[part 4 of 4: packages /BMW/Boardnet/Clusters/CommunicationClusters to /Systems/ModeDeclarationGroups/FunctionalPartialNetworks]
AUTOSAR XML (schema 4-3-0)
package /BMW/Boardnet/Clusters/CommunicationClusters  (continued)
  flexray cluster A_FlexRay:  (continued)
    flexray physical channel A_FlexRay: comm-connectors=con_EPS_FibexID_0b7e5e09c061465d913e8968ece3cded, channel-name=CHANNEL-A  (continued)
      frame DT_DRDYSEN_EXT_VYAW_VEH: to EPS, category=APPLICATION, frame-length=14, flexray-absolutely-scheduled-timing{communication-cycle=cycle-repetition={base-cycle=0, cycle-repetition=CYCLE-REPETITION-2}, slot-id=56}, allow-dynamic-l-sdu-length=false, payload-preamble-indicator=false  # Daten Fahrdynamiksensor Erweitert / Giergeschwindigkeit Fahrzeug
        carries pdu PDUs/VYAW_VEH: packing-byte-order=little-endian, start-position=64
        pdu VYAW_VEH: length=6, transmission-mode-true-timing=cyclic-timing=time-period=0.01, unused-bit-pattern=255  # Giergeschwindigkeit Fahrzeug | Gemessene und plausibilisierte Giergeschwindigkeit des Fahrzeugs. Diese Nachricht wird nicht im EntryHU Gateway der PL7 geroutet.
          signal ALIV_VYAW_VEH: start 8, 4 bit, little-endian, base-type=uint8, invalid-value=value_15Dot0:15, compu-method=CompuMethodsForBoardnet/ALIV_COU_4, to EPS  # Alive_Giergeschwindigkeit_Fahrzeug / alive_yaw-velocity_vehicle | LogicalInterface:BMW.POWERTRAIN.SpeedAccelerationDistance[external]@Fahren;
          signal CRC_VYAW_VEH: start 0, 8 bit, little-endian, base-type=uint8, compu-method=CompuMethodsForBoardnet/CRC8, data-constr=DataConstraints/CRC8, to EPS  # CRC_Giergeschwindigkeit_Fahrzeug / CRC_yaw-velocity_vehicle | LogicalInterface:BMW.POWERTRAIN.SpeedAccelerationDistance[external]@Fahren; Standardabsicherung Applikations-CRC Dieses Signal verwendet die Applikations-CRC-ID = 14 (Dez)
          signal QU_VYAW_VEH: start 44, 4 bit, little-endian, base-type=uint8, invalid-value=value_15Dot0:15, compu {8=Initialisierung (QU_VYAW_VEH_Initialisierung) (Tritt während der Initialisierungsphase auf bis Ist-Wert verfügbar (Vorbefüllung). Nutzsignal wird permanent mit Nutzwert 0 befüllt.), 1=SignalwertIstGueltigUndAbgesichertUndPlausibilisiert (QU_VYAW_VEH_SignalwertIstGueltigUndAbgesichertUndPlausibilisiert) (Nutzsignal verfügbar, bereitgestellt aus zwei Sensoren (nur bei redundanter Sensorik) elektrische und Modellüberwachung i.O. / BNE original name: Signalwert ist gültig und abgesichert und plausibilisiert), 9=SignalwertIstGueltigUndAbgesichertZustandSlashStatusTemporaer (QU_VYAW_VEH_SignalwertIstGueltigUndAbgesichertZustandSlashStatusTemporaer) (Nutzsignal verfügbar, bereitgestellt aus zwei Sensoren (nur bei redundanter Sensorik) elektrische und Modellüberwachung i.O. Es liegt eine Signaltoleranz aufgrund nicht abgeschlossenen Offsetabgleichs an. FuSi : Bei sicherheitsrelevanten Funktionen ist die Fehleramplitude auszuwerten / BNE original name: Signalwert ist gültig und abgesichert, Zustand/Status temporär), 2=SignalwertIstGueltig (QU_VYAW_VEH_SignalwertIstGueltig) (Nutzsignal verfügbar, bereitgestellt aus einem Sensor elektrische und Modellüberwachung i.O. / BNE original name: Signalwert ist gültig), 10=SignalwertIstGueltigZustandSlashStatusTemporaer (QU_VYAW_VEH_SignalwertIstGueltigZustandSlashStatusTemporaer) (Nutzsignal verfügbar, bereitgestellt aus einem Sensor elektrische und Modellüberwachung i.O. Es liegt eine Signaltoleranz aufgrund nicht abgeschlossenen Offsetabgleichs an. FuSi : Bei sicherheitsrelevanten Funktionen ist die Fehleramplitude auszuwerten. / BNE original name: Signalwert ist gültig, Zustand/Status temporär), 3=SignalqualitaetBzwDotUeberwachungEingeschraenkt (QU_VYAW_VEH_SignalqualitaetBzwDotUeberwachungEingeschraenkt) (keine Modellüberwachung, da Eingangsgrößen für Überwachung fehlen (zum Bsp. Querbeschleunigung, Lenkwinkel, ...), elektrische Überwachung i.O Nutzsignal wird aus Sensorwert gebildet. FuSi: keine Verwendung für sicherheitsrelevante Funktionen / BNE original name: Signalqualität bzw. Überwachung eingeschränkt), 11=SignalqualitaetBzwDotUeberwachungEingeschraenktZustandSlashStatusTemporaer (QU_VYAW_VEH_SignalqualitaetBzwDotUeberwachungEingeschraenktZustandSlashStatusTemporaer) (keine Modellüberwachung, da Eingangsgrößen für Überwachung fehlen (zum Bsp. Querbeschleunigung, Lenkwinkel, ...), elektrische Überwachung i.O Es liegt eine Signaltoleranz aufgrund nicht abgeschlossenen Offsetabgleichs an. Nutzsignal wird aus Sensorwert gebildet. FuSi : Bei sicherheitsrelevanten Funktionen ist die Fehleramplitude auszuwerten / BNE original name: Signalqualität bzw. Überwachung eingeschränkt, Zustand/Status temporär), 4=Reserved (QU_VYAW_VEH_Reserved), 12=ErsatzwertColonAbgleichwertIstImNutzsignalGesetztZustandSlashStatusTemporaer (QU_VYAW_VEH_ErsatzwertColonAbgleichwertIstImNutzsignalGesetztZustandSlashStatusTemporaer) (elektrische Überwachung oder Modellüberwachung zeigt Fehler an, deshalb wird Ersatzwert aus Modell (Lenkwinkel) versendet FuSi: keine Verwendung für sicherheitsrelevante Funktionen / BNE original name: Ersatzwert: Abgleichwert ist im Nutzsignal gesetzt, Zustand/Status temporär), 6=SignalwertIstUngueltig (QU_VYAW_VEH_SignalwertIstUngueltig) (elektrische Überwachung oder Modellüberwachung zeigt Fehler an, kein Ersatzwert verfügbar (Steuergerät interner Fehler). Das zugehörige Nutzsignal wird permanent mit der Ungültigkeitskennung befüllt. Diese Codierung wird ab SP2015 nicht mehr bedient. / BNE original name: Signalwert ist ungültig), 14=SignalwertIstUngueltigZustandSlashStatusTemporaer (QU_VYAW_VEH_SignalwertIstUngueltigZustandSlashStatusTemporaer) (elektrische Überwachung oder Modellüberwachung zeigt Fehler an, kein Ersatzwert verfügbar (Eingangssignale Fehler). Das zugehörige Nutzsignal wird permanent mit der Ungültigkeitskennung befüllt. / BNE original name: Signalwert ist ungültig, Zustand/Status temporär), 7=Reserved_bne_7C322122A3AD4C1BBA9012320D4729F1_7 (QU_VYAW_VEH_Reserved_bne_7C322122A3AD4C1BBA9012320D4729F1_7) (BNE original name: Reserved), 15=SignalUngueltig (QU_VYAW_VEH_SignalUngueltig) (Kann nur vom Gateway gesetzt werden / BNE original name: Signal ungültig)} "Qualifier_Giergeschwindigkeit_Fahrzeug / Qualifier_yaw-velocity_vehicle", to EPS  # Qualifier_Giergeschwindigkeit_Fahrzeug / Qualifier_yaw-velocity_vehicle | LogicalInterface:BMW.POWERTRAIN.SpeedAccelerationDistance[external]@Fahren; Erweiterter Status Qualifier zum Signal Giergeschwindigkeit_Fahrzeug. Mindestanforderungen um einen gültigen Signalwert senden zu können (Stand 10.06.08 gilt für L6/L7/F25): - Klemme 30B + Geschwindigkeit_Fahrzeug_Schwerpunkt gültig + Lenkwinkel_Vorderachse_effektiv gültig alternative Aufstartbedingung: - Bei Erkennung eines Modellfehlers wird bei Kl.15 Änderung ein Reset durchgeführt. Frühestens 50ms später kann ein gültiger Wert kommen. In dieser Zeit wird der Qualifier auf Initialisierung gesetzt. Ab der F010-10-01-350 gibt es baureihenübergreifend folgende Spezifikationsänderung: Wenn der Gierratensensor im Anschlag ist (z. Bsp. bei der Rückwärtsschleuderwende), wird nicht wie bisher auf VYAW_VEH ein Ersatzwert und im Qualifier die Codierung 12 (dec) gesendet, sondern es wird der begrenzte Wert ausgegeben und der Qualifier bleibt auf gültig.
          signal VYAW_VEH: start 16, 16 bit, little-endian, base-type=uint16, invalid-value=value_65535Dot0:65535, compu {phys=raw*0.005-163.84 for raw 32768..13139567.999999998; unit °/s} "Transp.MOST-GW-Migration, 01.09.2006: Zusammenführung der Signalklasse Giergeschwindigkeit_Fahrzeug [1] mit den Parametern YawVelocityVehicle [1].", range phys 0..65534 °/s "Transp.MOST-GW-Migration, 01.09.2006: Zusammenführung der Signalklasse Giergeschwindigkeit_Fahrzeug [1] mit den Parametern YawVelocityVehicle [1].", to EPS  # Giergeschwindigkeit_Fahrzeug / yaw-velocity_vehicle | LogicalInterface:BMW.POWERTRAIN.SpeedAccelerationDistance[external]@Fahren; Giergeschwindigkeit des Fahrzeugs. Richtung nach ISO 8855 (positiver Winkel entspricht Drehung gegen den Uhrzeigersinn). Die Giergeschwindigkeit des Fahrzeuges wird je nach Fahrzeugkonfiguration von einem oder zwei Gierratensensoren gemessen. Es erfolgt eine Plausibilisierung (durch Modellüberwachung, Gradientenüberwachung und Redundanzüberwachung bei zwei Sensoren) und ein Langzeitabgleich der Offset-Drifts. Sind zwei Gierratensensoren verbaut, so wird der Mittelwert der abgeglichenen Signale als Gierratennutzsignal ausgegeben. Ist einer von zwei Gierratensensoren als fehlerhaft erkannt, so wird der Wert des verbleibenden Sensors als Nutzsignal ausgegeben. Im Qualifier erfolgt die Rückstufung des Signals von "gültig + abgesichert" auf "gültig". Die Einstufung "gültig" gilt entsprechend auch dann, wenn nur ein Gierratensensor verbaut und fehlerfrei ist. Sind alle im Fzg. verbauten Gierratensensoren als fehlerhaft erkannt, so wird ein Ersatzwert aus den verbleibenden Sensoren im Fzg. (Raddrehzahlen, Lenkwinkel, Querbeschleunigung) berechnet und ausgegeben. Entsprechend erfolgt die Kennzeichnung "Ersatzwert" durch den Qualifier. Transp.MOST-GW-Migration, 01.09.2006: Zusammenführung des Parameters YawVelocityVehicle [1] mit dem Signal Giergeschwindigkeit_Fahrzeug [3].
          signal VYAW_VEH_ERR_AMP: start 32, 12 bit, little-endian, base-type=uint16, invalid-value=value_4095Dot0:4095, compu {phys=raw*0.0125 for raw 0..320000; unit °/s} "Quantisierung ist temporär", range phys 0..4000 °/s "Quantisierung ist temporär", to EPS  # Giergeschwindigkeit_Fahrzeug_Fehler_Amplitude / yaw-velocity_vehicle_error_amplitude | LogicalInterface:BMW.POWERTRAIN.SpeedAccelerationDistance[external]@Fahren; Für den Fall, dass ein Sensorfehler nicht oder noch nicht erkannt wurde, interne Überwachungsmaßnahmen jedoch anzeigen, dass eine Abweichung des Sensorsignals vom tatsächlichen Wert vorliegen könnte, gibt dieser Wert an, wie groß diese Abweichung maximal sein kann. Es wird der Betrag der Fehleramplitude ausgegeben, die Abweichung des tatsächlichen Signals vom ausgegebenen Signal liegt in einem Band mit der doppelten Breite der Fehleramplitude (Signal plus oder minus Fehleramplitude). Der Qualifier des Nutzsignals behält in diesem Fall seinen bisherigen Wert. Beispiel: zwei nicht als fehlerhaft erkannte Gierratensensoren liefern die Werte 10°/s und 20°/s. Das ausgegebene Nutzsignal hat in diesem Fall einen Wert von 15°/s, die Fehleramplitude einen Wert von 5°/s.
          signal VYAW_VEH_dummy_12_15: start 12, 4 bit, little-endian, base-type=uint8, compu {identical}, range phys 0..15, to EPS
          mapping sigGroup_VYAW_VEH: i-signal-group=sigGroup_VYAW_VEH
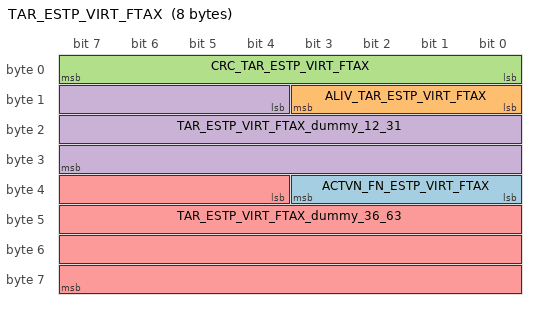
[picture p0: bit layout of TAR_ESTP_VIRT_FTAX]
      frame TAR_ESTP_VIRT_FTAX: to EPS, category=APPLICATION, frame-length=8, flexray-absolutely-scheduled-timing{communication-cycle=cycle-repetition={base-cycle=1, cycle-repetition=CYCLE-REPETITION-2}, slot-id=65}, allow-dynamic-l-sdu-length=false, payload-preamble-indicator=false  # Soll Endanschlag Virtuell Vorderachse
        pdu TAR_ESTP_VIRT_FTAX: length=8, transmission-mode-true-timing=cyclic-timing=time-period=0.01, unused-bit-pattern=255  # Soll Endanschlag Virtuell Vorderachse
          signal ACTVN_FN_ESTP_VIRT_FTAX: start 32, 4 bit, little-endian, base-type=uint8, invalid-value=value_15Dot0:15, compu {0=FunktionVirtuellerEndanschlagDeaktivieren (ACTVN_FN_ESTP_VIRT_FTAX_FunktionVirtuellerEndanschlagDeaktivieren) (Funktion virtueller Endanschlag deaktivieren durch Fahrzeugführung / BNE original name: Funktion virtueller Endanschlag deaktivieren), 1=FunktionVirtuellerEndanschlagAktivieren (ACTVN_FN_ESTP_VIRT_FTAX_FunktionVirtuellerEndanschlagAktivieren) (Funktion virtueller Endanschlag aktivieren durch Fahrzeugführung / BNE original name: Funktion virtueller Endanschlag aktivieren), 13=Funktionsschnittstelle_ist_nicht_verfuegbar (ACTVN_FN_ESTP_VIRT_FTAX_Funktionsschnittstelle_ist_nicht_verfuegbar) (Sendefunktion in Betrieb, Werte nicht verfügbar), 14=Funktion_meldet_Fehler (ACTVN_FN_ESTP_VIRT_FTAX_Funktion_meldet_Fehler) (Sendefunktion in Betrieb, meldet Fehler), 15=Signal_unbefuellt (ACTVN_FN_ESTP_VIRT_FTAX_Signal_unbefuellt) (Sendefunktion nicht in Betrieb)} "Aktivierung_Funktion_Endanschlag_Virtuell_Vorderachse / activation_function_end-stop_virtual_front-axle", to EPS  # Aktivierung_Funktion_Endanschlag_Virtuell_Vorderachse / activation_function_end-stop_virtual_front-axle | LogicalInterface:BMW.CHASSIS.STEERING.SteeringAngle[internal]@Fahren; Dieses Signal gibt an, ob der virtuelle Endanschlag der EPS aktiviert bzw. deaktiviert werden soll.
          signal ALIV_TAR_ESTP_VIRT_FTAX: start 8, 4 bit, little-endian, base-type=uint8, invalid-value=value_15Dot0:15, compu {identical}, range phys 0..14, to EPS  # Alive_Soll_Endanschlag_Virtuell_Vorderachse / alive_target_end-stop_virtual_front-axle | LogicalInterface:BMW.CHASSIS.STEERING.SteeringAngle[internal]@Fahren; Standardabsicherung Alivezähler laut Definition per Lastenheft Allgemeine Bordnetzkommunikation Dieses Signal soll nur überwacht werden, wenn Aktivlenkung und ein Lenksäulensteller verbaut sind.
          signal CRC_TAR_ESTP_VIRT_FTAX: start 0, 8 bit, little-endian, base-type=uint8, compu-method=CompuMethodsForBoardnet/CRC8, data-constr=DataConstraints/CRC8, to EPS  # CRC_Soll_Endanschlag_Virtuell_Vorderachse / CRC_target_end-stop_virtual_front-axle | LogicalInterface:BMW.CHASSIS.STEERING.SteeringAngle[internal]@Fahren; Dieses Signal verwendet die Applikations-CRC-ID = 52 (Dez) Dieses Signal soll nur überwacht werden, wenn Aktivlenkung und ein Lenksäulensteller verbaut sind.
          signal TAR_ESTP_VIRT_FTAX_dummy_12_31: start 12, 20 bit, little-endian, base-type=uint32, compu {identical}, range phys 0..1048575, to EPS
          signal TAR_ESTP_VIRT_FTAX_dummy_36_63: start 36, 28 bit, little-endian, base-type=uint32, compu {identical}, range phys 0..268435455, to EPS
          mapping sigGroup_TAR_ESTP_VIRT_FTAX: i-signal-group=sigGroup_TAR_ESTP_VIRT_FTAX
      frame TAR_QTA_STRMOM_DV_TAR_STMOM_DV_ACT: to EPS, category=APPLICATION, frame-length=16, flexray-absolutely-scheduled-timing{communication-cycle=cycle-repetition={base-cycle=0, cycle-repetition=CYCLE-REPETITION-2}, slot-id=68}, allow-dynamic-l-sdu-length=false, payload-preamble-indicator=false  # Soll Anteil Lenkmoment Fahrer / Soll Lenkmoment Fahrer Stellglied / target quota steering-moment driver / Soll Lenkmoment Fahrer Stellglied | Soll-Offset-Handmoment.
        pdu TAR_QTA_STRMOM_DV: length=8, transmission-mode-true-timing=cyclic-timing=time-period=0.01, unused-bit-pattern=255  # Soll Anteil Lenkmoment Fahrer / target quota steering-moment Fahrer | Diese Nachricht wird nur bei Fahrzeugen mit elektrischer Lenkung unterstützt. Soll-Offset-Handmoment
          signal ALIV_TAR_QTA_STMOM_DV: start 8, 4 bit, little-endian, base-type=uint8, invalid-value=value_15Dot0:15, compu-method=CompuMethodsForBoardnet/ALIV_COU_4, to EPS  # Alive_Soll_Anteil_Lenkmoment_Fahrer / alive_target_quota_steering-moment_driver | LogicalInterface:BMW.CHASSIS.STEERING.SteeringAngle[internal]@Fahren; Standardabsicherung Alivezähler laut Definition per Lastenheft Allgemeine Bordnetzkommunikation.
          signal CRC_TAR_QTA_STMOM_DV: start 0, 8 bit, little-endian, base-type=uint8, compu-method=CompuMethodsForBoardnet/CRC8, data-constr=DataConstraints/CRC8, to EPS  # CRC_Soll_Anteil_Lenkmoment_Fahrer / CRC_target_quota_steering-moment_driver | LogicalInterface:BMW.CHASSIS.STEERING.SteeringAngle[internal]@Fahren; Standardabsicherung Applikations-CRC laut Definition per Lastenheft Allgemeine Bordnetzkommunikation. Dieses Signal verwendet die Applikations-CRC-ID = 109 (Dez)
          signal CTR_DEAC_EPS_FNS: start 60, 4 bit, little-endian, base-type=uint8, invalid-value=value_15Dot0:15, compu {mask 15: 0=Keine_Deaktivierung_EPS_Funktionen (CTR_DEAC_EPS_FNS_Keine_Deaktivierung_EPS_Funktionen) (Es besteht keine Anforderung zur Deaktivierung von Funktionen auf der EPS.), mask 15: 13=Funktionsschnittstelle_ist_nicht_verfuegbar (CTR_DEAC_EPS_FNS_Funktionsschnittstelle_ist_nicht_verfuegbar) (Sendefunktion in Betrieb, Werte nicht verfügbar), mask 15: 14=Funktion_meldet_Fehler (CTR_DEAC_EPS_FNS_Funktion_meldet_Fehler) (Sendefunktion in Betrieb, meldet Fehler), mask 15: 15=Signal_unbefuellt (CTR_DEAC_EPS_FNS_Signal_unbefuellt) (Wird nicht aktiv gesetzt), mask 9: 1=Deaktivierung_EPS_Funktionen_Funktionsgruppe_1 (CTR_DEAC_EPS_FNS_Deaktivierung_EPS_Funktionen_Funktionsgruppe_1) (Anforderung zur Deaktivierung einer spezifizierten Funktionsgruppe 1 auf der EPS. Die detaillierte Spezifikation der Funktionsgruppe 1 erfolgt im Entwicklungsprozess mit den Lieferanten. / BNE original name: Deaktivierung_EPS_Funktionen_ Funktionsgruppe_1), mask 10: 2=Deaktivierung_EPS_Funktionen_Funktionsgruppe_2 (CTR_DEAC_EPS_FNS_Deaktivierung_EPS_Funktionen_Funktionsgruppe_2) (Anforderung zur Deaktivierung einer spezifizierten Funktionsgruppe 2 auf der EPS. Die detaillierte Spezifikation der Funktionsgruppe 2 erfolgt im Entwicklungsprozess mit den Lieferanten. / BNE original name: Deaktivierung_EPS_Funktionen_ Funktionsgruppe_2)} "Steuerung_Deaktivierung_EPS_Funktionen / control_deactivation_EPS_functions", to EPS  # Steuerung_Deaktivierung_EPS_Funktionen / control_deactivation_EPS_functions | LogicalInterface:BMW.CHASSIS.STEERING.SteeringAngle[internal]@Fahren; Dieses Signal beinhaltet die Information zur Deaktivierung einzelner Funktionen auf der EPS.
          signal FACT_ASS_STMOM_FTAX: start 48, 8 bit, little-endian, base-type=uint8, invalid-value=value_255Dot0:255, compu {phys=raw/256+1 for raw -256..64768}, range phys 0..254, to EPS  # Faktor_Unterstützung_Lenkmoment_Vorderachse / factor_assistance_steering-moment_front-axle | LogicalInterface:BMW.CHASSIS.STEERING.SteeringAngle[internal]@Fahren; Dieser Faktor wird als Multiplikator für den Steuerung der Lenkunterstützungsberechnung benötigt. Vollständige Quantisierung/Offsetsangabe: (PH) = 0.00390625 * (HEX) + 1
          signal FACT_CTRR_STMOM_FTAX: start 32, 8 bit, little-endian, base-type=uint8, invalid-value=value_255Dot0:255, compu {phys=raw/256+0.0078125 for raw -2..65022}, range phys 0..254, to EPS  # Faktor_Zentrierung_Lenkmoment_Vorderachse / factor_centering_steering-moment_front-axle | LogicalInterface:BMW.CHASSIS.STEERING.SteeringAngle[internal]@Fahren; Dieser Faktor wird als Multiplikator für den Steuerung des Aktiven Rücklaufs benötigt. Vollständige Quantisierung/Offsetsangabe: (PH) = 0.00390625 * (HEX) + 0,0078125
          signal FACT_DMPNG_STMOM_FTAX: start 40, 8 bit, little-endian, base-type=uint8, invalid-value=value_255Dot0:255, compu {phys=raw/256+0.0078125 for raw -2..65022}, range phys 0..254, to EPS  # Faktor_Dämpfung_Lenkmoment_Vorderachse / factor_damping_steering-moment_front-axle | LogicalInterface:BMW.CHASSIS.STEERING.SteeringAngle[internal]@Fahren; Dieser Faktor wird als Multiplikator für den Steuerung des Aktiven Rücklaufs benötigt. Vollständige Quantisierung/Offsetsangabe: (PH) = 0.00390625 * (HEX) + 0.0078125
          signal QU_TAR_FACT_STMOM_FTAX: start 56, 4 bit, little-endian, base-type=uint8, invalid-value=value_15Dot0:15, compu {2=SollwerteUmsetzen (QU_TAR_FACT_STMOM_FTAX_SollwerteUmsetzen) (Es wird ein Lenkmoment angefordert. / BNE original name: Sollwerte umsetzen), 7=SollwerteNichtVorhanden (QU_TAR_FACT_STMOM_FTAX_SollwerteNichtVorhanden) (Wird immer gesetzt wenn keine EPS verbaut ist. / BNE original name: Sollwerte nicht vorhanden), 14=StandbyColonSollwerteNichtUmsetzen (QU_TAR_FACT_STMOM_FTAX_StandbyColonSollwerteNichtUmsetzen) (Es wird kein Moment angefordert. Wird auch im Fehlerfall gesetzt. / BNE original name: Standby: Sollwerte nicht umsetzen), 15=SignalUngueltig (QU_TAR_FACT_STMOM_FTAX_SignalUngueltig) (Wird nicht aktiv gesetzt / BNE original name: Signal ungültig)} "Qualifier_Soll_Faktor_Lenkmoment_Vorderachse / Qualifier_target_factor_steering-moment_front-axle", to EPS  # Qualifier_Soll_Faktor_Lenkmoment_Vorderachse / Qualifier_target_factor_steering-moment_front-axle | LogicalInterface:BMW.CHASSIS.STEERING.SteeringAngle[internal]@Fahren; Sollwertqualifier zu den Signalen Faktor_Unterstützung_Lenkmoment_Vorderachse, Faktor_Dämpfung_Lenkmoment_Vorderachse, Faktor_Zentrierung_Lenkmoment_Vorderachse
          signal QU_TAR_QTA_STMOM_DV: start 28, 4 bit, little-endian, base-type=uint8, invalid-value=value_15Dot0:15, compu {2=SollwerteUmsetzen (QU_TAR_QTA_STMOM_DV_SollwerteUmsetzen) (Es wird ein Lenkmoment angefordert. / BNE original name: Sollwerte umsetzen), 7=SollwerteNichtVorhanden (QU_TAR_QTA_STMOM_DV_SollwerteNichtVorhanden) (Wird gesendet, wenn die Funktion auscodiert ist. Wird immer gesetzt wenn keine EPS verbaut ist. / BNE original name: Sollwerte nicht vorhanden), 14=SollwerteNichtUmsetzen_Standby (QU_TAR_QTA_STMOM_DV_SollwerteNichtUmsetzen_Standby) (Es wird kein Moment angefordert. / BNE original name: Sollwerte nicht umsetzen - Standby), 15=SignalUngueltig (QU_TAR_QTA_STMOM_DV_SignalUngueltig) (Wird nicht aktiv gesetzt / BNE original name: Signal ungültig)} "Qualifier_Soll_Anteil_Lenkmoment_Fahrer / Qualifier_target_quota_steering-moment_driver", to EPS  # Qualifier_Soll_Anteil_Lenkmoment_Fahrer / Qualifier_target_quota_steering-moment_driver | LogicalInterface:BMW.CHASSIS.STEERING.SteeringAngle[internal]@Fahren; Sollwert-Qualifier zum Signal Soll_Anteil_Lenkmoment_Fahrer
          signal TAR_QTA_STMOM_DV: start 16, 12 bit, little-endian, base-type=uint16, invalid-value=value_4095Dot0:4095, compu {phys=raw*0.005-10 for raw 2000..802000; unit NwtMtr}, range phys 0..4000 NwtMtr, to EPS  # Soll_Anteil_Lenkmoment_Fahrer / target_quota_steering-moment_driver | LogicalInterface:BMW.CHASSIS.STABILIZATION.VehicleDynamicParameters[internal]@Fahren; Es handelt sich um das Offset-Handmoment des Lenkrades, das im Gegenuhrzeigersinn positiv gezählt wird.
          signal TAR_QTA_STRMOM_DV_dummy_12_15: start 12, 4 bit, little-endian, base-type=uint8, compu {identical}, range phys 0..15, to EPS
          mapping sigGroup_TAR_QTA_STRMOM_DV: i-signal-group=sigGroup_TAR_QTA_STRMOM_DV
        carries pdu PDUs/TAR_STMOM_DV_ACT: packing-byte-order=little-endian, start-position=64
        pdu TAR_STMOM_DV_ACT: length=8, transmission-mode-true-timing=cyclic-timing=time-period=0.01, unused-bit-pattern=255  # Soll Lenkmoment Fahrer Stellglied | Diese Nachricht wird nur bei Fahrzeugen mit elektrischer Lenkung unterstützt. Das angegebene Offsetmoment wird vom ICM_QL Momentkoordinator gesendet und hinter der Reglerschleife aufaddiert, um eine direkte Korrekturmöglichkeit der Stellwerte zu haben.
          signal ALIV_TAR_STMOM_DV_ACT: start 8, 4 bit, little-endian, base-type=uint8, invalid-value=value_15Dot0:15, compu-method=CompuMethodsForBoardnet/ALIV_COU_4, to EPS  # Alive_Soll_Lenkmoment_Fahrer_Stellglied / alive_target_steering-moment_driver_actuator | LogicalInterface:BMW.CHASSIS.STABILIZATION.VehicleDynamicParameters[internal]@Fahren; Standardabsicherung Alivezähler laut Definition per Lastenheft Allgemeine Bordnetzkommunikation.
          signal CRC_TAR_STMOM_DV_ACT: start 0, 8 bit, little-endian, base-type=uint8, compu-method=CompuMethodsForBoardnet/CRC8, data-constr=DataConstraints/CRC8, to EPS  # CRC_Soll_Lenkmoment_Fahrer_Stellglied / CRC_target_steering-moment_driver_actuator | LogicalInterface:BMW.CHASSIS.STABILIZATION.VehicleDynamicParameters[internal]@Fahren; Standardabsicherung Applikations-CRC laut Definition per Lastenheft Allgemeine Bordnetzkommunikation. Dieses Signal verwendet die Applikations-CRC-ID = 179 (Dez)
          signal FACT_DMPNG_ADDON_STMOM_FTAX: start 56, 8 bit, little-endian, base-type=uint8, invalid-value=value_255Dot0:255, compu {phys=raw/64 for raw 0..8192, 253=Reserviert (FACT_DMPNG_ADDON_STMOM_FTAX_Reserviert) (Hinweis: Reserviert für funktionale Kennung Signal-Tag.), 254=Reserviert_bne_5B8A124DE2884D68A663388C50F241EF_254 (FACT_DMPNG_ADDON_STMOM_FTAX_Reserviert_bne_5B8A124DE2884D68A663388C50F241EF_254) (Hinweis: Reserviert für funktionale Kennung Signal-Tag. / BNE original name: Reserviert), 255=Signal_unbefuellt (FACT_DMPNG_ADDON_STMOM_FTAX_Signal_unbefuellt) (Sendefunktion nicht in Betrieb)} "Faktor_Dämpfung_Zusatz_Lenkmoment_Vorderachse / factor_damping_add-on_steering-moment_front-axle", range phys 0..128 "Faktor_Dämpfung_Zusatz_Lenkmoment_Vorderachse / factor_damping_add-on_steering-moment_front-axle", to EPS  # Faktor_Dämpfung_Zusatz_Lenkmoment_Vorderachse / factor_damping_add-on_steering-moment_front-axle | LogicalInterface:BMW.CHASSIS.STABILIZATION.VehicleDynamicParameters[internal]@Fahren; Skalierung der Zusatzdämpfung in der EPS für steife Lenkwinkelregelung in der SWC QdmZff.
          signal QU_TAR_DMPNG_ADDON_STMOM_FTAX: start 52, 4 bit, little-endian, base-type=uint8, invalid-value=value_15Dot0:15, compu {1=SollwertZusatzdaempfungNichtUmsetzen (QU_TAR_DMPNG_ADDON_STMOM_FTAX_SollwertZusatzdaempfungNichtUmsetzen) (BNE original name: Sollwert Zusatzdämpfung nicht umsetzen), 2=SollwertZusatzdaempfungUmsetzen (QU_TAR_DMPNG_ADDON_STMOM_FTAX_SollwertZusatzdaempfungUmsetzen) (BNE original name: Sollwert Zusatzdämpfung umsetzen), 15=SignalUnbefuellt (QU_TAR_DMPNG_ADDON_STMOM_FTAX_SignalUnbefuellt) (Wird nicht aktiv gesetzt / BNE original name: Signal unbefüllt)} "Qualifier_Soll_Dämpfung_Zusatz_Lenkmoment_Vorderachse / Qualifier_target_damping_add-on_steering-moment_front-axle", to EPS  # Qualifier_Soll_Dämpfung_Zusatz_Lenkmoment_Vorderachse / Qualifier_target_damping_add-on_steering-moment_front-axle | LogicalInterface:BMW.CHASSIS.STABILIZATION.VehicleDynamicParameters[internal]@Fahren; Sollwertqualifier zum Signal Faktor_Dämpfung_Zusatz_Lenkmoment_Vorderachse
          signal QU_TAR_STMOM_DV_ACT: start 28, 4 bit, little-endian, base-type=uint8, invalid-value=value_15Dot0:15, compu {2=SollwerteUmsetzen (QU_TAR_STMOM_DV_ACT_SollwerteUmsetzen) (Es wird ein Lenkmoment angefordert. / BNE original name: Sollwerte umsetzen), 7=SollwerteNichtVorhanden (QU_TAR_STMOM_DV_ACT_SollwerteNichtVorhanden) (Wird immer gesetzt wenn keine EPS verbaut ist / BNE original name: Sollwerte nicht vorhanden), 14=StandbyColonSollwerteNichtUmsetzen (QU_TAR_STMOM_DV_ACT_StandbyColonSollwerteNichtUmsetzen) (Es wird kein Moment angefordert. Wird auch im Fehlerfall gesetzt. / BNE original name: Standby: Sollwerte nicht umsetzen), 15=SignalUngueltig (QU_TAR_STMOM_DV_ACT_SignalUngueltig) (Wird nicht aktiv gesetzt / BNE original name: Signal ungültig)} "Qualifier_Soll_Lenkmoment_Fahrer_Stellglied / Qualifier_target_steering-moment_driver_actuator", to EPS  # Qualifier_Soll_Lenkmoment_Fahrer_Stellglied / Qualifier_target_steering-moment_driver_actuator | LogicalInterface:BMW.CHASSIS.STABILIZATION.VehicleDynamicParameters[internal]@Fahren; Sollwertqualifier zum Signal Soll_Lenkmoment_Fahrer_Stellglied
          signal TAR_STMOM_DV_ACT: start 16, 12 bit, little-endian, base-type=uint16, invalid-value=value_4095Dot0:4095, compu {phys=raw*0.006-12 for raw 2000..668666.6666666666; unit NwtMtr}, range phys 0..4000 NwtMtr, to EPS  # Soll_Lenkmoment_Fahrer_Stellglied / target_steering-moment_driver_actuator | LogicalInterface:BMW.CHASSIS.STABILIZATION.VehicleDynamicParameters[internal]@Fahren; Gestelltes Motormoment für den EPS Aktuator. Offsetmoment (+/-1Nm).
          signal TAR_STMOM_DV_ACT_dummy_12_15: start 12, 4 bit, little-endian, base-type=uint8, compu {identical}, range phys 0..15, to EPS
          signal TAR_STMOM_DV_ACT_dummy_32_51: start 32, 20 bit, little-endian, base-type=uint32, compu {identical}, range phys 0..1048575, to EPS
          mapping sigGroup_TAR_STMOM_DV_ACT: i-signal-group=sigGroup_TAR_STMOM_DV_ACT
      frame ENERG_DGR_DRDY: to EPS, category=APPLICATION, frame-length=8, flexray-absolutely-scheduled-timing{communication-cycle=cycle-repetition={base-cycle=1, cycle-repetition=CYCLE-REPETITION-2}, slot-id=68}, allow-dynamic-l-sdu-length=false, payload-preamble-indicator=false  # Energie Degradation Fahrdynamik
        pdu ENERG_DGR_DRDY: length=8, transmission-mode-true-timing=cyclic-timing=time-period={tolerance=absolute-tolerance=0.002, value=0.01}, unused-bit-pattern=255  # Energie Degradation Fahrdynamik | Energie Degradation fahrdynamischer Regelsysteme: Diese PDU enthält die Max-Strom-Vorgaben für EPS, ASA, HSR, emARS und einen Funktionsqualifier zur Degradation von EHC1/2
          signal MAX_I_SPEC_EPS: start 0, 8 bit, little-endian, base-type=uint8, invalid-value=value_255Dot0:255, compu-method=CompuMethodsForBoardnet/I_SPEC_ARS, data-constr=DataConstraints/I_SPEC_ARS, to EPS  # Maximal_Strom_Vorgabe_EPS / maximum_current_specification_EPS | LogicalInterface:BMW.POWERTRAIN.GENERATOR.EnergyManagementDrive[internal]@Fahren; Es handel sich um den maximal zulässigen DC-Last-Strom am Stecker der elektrischen Lenkmomentenunterstützung (EPS-Motor). Default-Wert ist 120 A.
      frame xcpstatic: from EPS, category=XCP_RUNTIME_CONFIGURED, frame-length=16, flexray-absolutely-scheduled-timing{communication-cycle=cycle-repetition={base-cycle=0, cycle-repetition=CYCLE-REPETITION-1}, slot-id=8}, allow-dynamic-l-sdu-length=false, payload-preamble-indicator=false  # XCP Bereich Statisch / XCP Frame Static | Dieser Frame dient als Platzhalter für die XCP-Konfiguration für FlexRay (s. LH FlexRay) und zur Pufferkonfiguration der FlexRay-Controller. Der statische XCP-Bereich wird auch durch das Projekt "Funktionstrace" mitbenutzt. Ansprechpartner ist Florian Kuttig oder Christian Pigorsch. / Dummyframe für Infrastruktur XCP
        carries pdu dummy16bstatic: packing-byte-order=little-endian, start-position=0
      frame xcpstatic: from EPS, category=XCP_RUNTIME_CONFIGURED, frame-length=16, flexray-absolutely-scheduled-timing{communication-cycle=cycle-repetition={base-cycle=0, cycle-repetition=CYCLE-REPETITION-1}, slot-id=9}, allow-dynamic-l-sdu-length=false, payload-preamble-indicator=false  # XCP Bereich Statisch / XCP Frame Static | Dieser Frame dient als Platzhalter für die XCP-Konfiguration für FlexRay (s. LH FlexRay) und zur Pufferkonfiguration der FlexRay-Controller. Der statische XCP-Bereich wird auch durch das Projekt "Funktionstrace" mitbenutzt. Ansprechpartner ist Florian Kuttig oder Christian Pigorsch. / Dummyframe für Infrastruktur XCP
        carries pdu dummy16bstatic: packing-byte-order=little-endian, start-position=0
      pdu triggering pduTrig_ANFRAGE: pdu=PDUs/ANFRAGE, from EPS, to EPS
      pdu triggering pduTrig_DBG_EPS_BS_MOD_58_BYTE: pdu=PDUs/DBG_EPS_BS_MOD_58_BYTE, from EPS
      pdu triggering pduTrig_DBG_EPS_MOD_EXT_120_BYTE: pdu=PDUs/DBG_EPS_MOD_EXT_120_BYTE, from EPS
      pdu triggering pduTrig_RQ_STG_EFAN: pdu=PDUs/RQ_STG_EFAN, from EPS
      pdu triggering pduTrig_SECU_CHAL: pdu=PDUs/SECU_CHAL, from EPS
      pdu triggering pduTrig_SECU_RESP: pdu=PDUs/SECU_RESP, to EPS
package /BMW/Boardnet/CodingDatatypes/CompuMethodsForBoardnet
  compu method ALIV_COU_4: 0=Zaehlerstand0DotDotE (ALIV_COU_4_Zaehlerstand0DotDotE) (Nach dem Zählerstand 14 wird zyklisch bei 0 wieder begonnen. / After counter reading 14, the counter restarts at 0 again in cycles / BNE original name: Zählerstand 0..E), 15=SignalUngueltig (ALIV_COU_4_SignalUngueltig) (BNE original name: Signal ungültig)  # Alive_Zähler_4 / alive_counter_4
  compu method CRC8: identical  # Standartabsicherung Apllikations-CRC.
  compu method DIAG_ST_OBD: identical  # Diagnose_Status_OBD / diagnosis_status_OBD
  compu method I_SPEC_ARS: 0..252, 253=Funktionsschnittstelle_ist_nicht_verfuegbar (I_SPEC_ARS_Funktionsschnittstelle_ist_nicht_verfuegbar) (Sendefunktion in Betrieb, Werte nicht verfügbar), 254=Funktion_meldet_Fehler (I_SPEC_ARS_Funktion_meldet_Fehler) (Nutzsignal kann nicht berechnet werden), 255=Signal_unbefuellt (I_SPEC_ARS_Signal_unbefuellt) (Sendefunktion nicht in Betrieb); unit A  # Strom_Vorgabe_ARS / current_specification_ARS
  compu method MAX_I_SPEC_SFY: 0..252, 253=Reserviert_nicht_verfuegbar (MAX_I_SPEC_SFY_Reserviert_nicht_verfuegbar) (Hinweis: Reserviert für funktionale Kennung Signal-Tag.), 254=Reserviert_Fehler (MAX_I_SPEC_SFY_Reserviert_Fehler) (Hinweis: Reserviert für funktionale Kennung Signal-Tag.), 255=Signal_unbefuellt (MAX_I_SPEC_SFY_Signal_unbefuellt) (Sendefunktion nicht in Betrieb); unit A  # Maximal_Strom_Vorgabe_Sicherheit / maximum_current_specification_safety
  compu method QU_AVL_RPM_WHL: 8=Initialisierung (QU_AVL_RPM_WHL_Initialisierung) (Wird gelegt solange aufgrund des Aufstartvorgangs (und der dazu gehörenden Sensorprüfung) für den zugehörigen Raddrehzahlsensor kein Wert ermittelt werden kann. Nutzsignal wird permanent mit der Ungültigkeitskennung befüllt.), 1=SignalwertIstGueltigUndAbgesichertUndPlausibilisiert (QU_AVL_RPM_WHL_SignalwertIstGueltigUndAbgesichertUndPlausibilisiert) (Ist der zugehörige Raddrehzahlsensor i.O. geprüft, so wird der Qualifier auf diesem Zustand gesetzt. / BNE original name: Signalwert ist gültig und abgesichert und plausibilisiert), 9=Reserved (QU_AVL_RPM_WHL_Reserved), 2=Reserved_bne_BFE56DC998394BD9A8FED9E096CC9242_2 (QU_AVL_RPM_WHL_Reserved_bne_BFE56DC998394BD9A8FED9E096CC9242_2) (BNE original name: Reserved), 10=Reserved_bne_BFE56DC998394BD9A8FED9E096CC9242_10 (QU_AVL_RPM_WHL_Reserved_bne_BFE56DC998394BD9A8FED9E096CC9242_10) (BNE original name: Reserved), 3=Reserved_bne_BFE56DC998394BD9A8FED9E096CC9242_3 (QU_AVL_RPM_WHL_Reserved_bne_BFE56DC998394BD9A8FED9E096CC9242_3) (BNE original name: Reserved), 11=SignalqualitaetBzwDotUeberwachungEingeschraenktZustandSlashStatusTemporaer (QU_AVL_RPM_WHL_SignalqualitaetBzwDotUeberwachungEingeschraenktZustandSlashStatusTemporaer) (Implementierungsinfo des DSC-8 Bosch-Systems: Wird gelegt, wenn bei gesetzter Rollenerkennung des ICM-Q/L die Anfahrüberwachung des DSC zuschlägt. / BNE original name: Signalqualität bzw. Überwachung eingeschränkt, Zustand/Status temporär), 4=ErsatzwertIstImNutzsignalGesetzt (QU_AVL_RPM_WHL_ErsatzwertIstImNutzsignalGesetzt) (Wird gelegt, solange keine gültige Drehrichtung erkannt wurde. (z.B. Stillstand) Kann nur bei Sensoren mit Drehrichtungserkennung gesetzt werden. / BNE original name: Ersatzwert ist im Nutzsignal gesetzt), 12=ErsatzwertIstImNutzsignalGesetztZustandSlashStatusTemporaer (QU_AVL_RPM_WHL_ErsatzwertIstImNutzsignalGesetztZustandSlashStatusTemporaer) (Nutzsignal liefert das aktuelle Rohsignal mit eingeschränkter Qualität (es kann zu Abweichungen kommen). Der Übergang zum "Signalwert ist gültig" (0001) erfolgt über eine Einschwingphase (ca. 300ms) Kann auftreten während bzw. nach Unterspannung am Raddrehzahlsensor (DSC) In der PL6 wird dieser Code nicht verwendet. / BNE original name: Ersatzwert ist im Nutzsignal gesetzt Zustand / Status Temporär), 6=Wert_nicht_verfuegbar_Fehler_elektrisch (QU_AVL_RPM_WHL_Wert_nicht_verfuegbar_Fehler_elektrisch) (Im Fehlerfall wird abhängig von der Ursache entweder 0110 (Schwerpunkt: elektrische Fehler mit Reparaturbedarf) oder 1110 (Schwerpunkt: Plausibilitätsfehler ohne Reparaturbedarf) gesendet. Die Umsetzung ist produktlinienspezifisch unterschiedlich. Nutzsignal wird permanent mit der Ungültigkeitskennung befüllt.), 14=Wert_nicht_verfuegbar_Plausibilitaetsfehler (QU_AVL_RPM_WHL_Wert_nicht_verfuegbar_Plausibilitaetsfehler) (Im Fehlerfall wird abhängig von der Ursache entweder 0110 (Schwerpunkt: elektrische Fehler mit Reparaturbedarf) oder 1110 (Schwerpunkt: Plausibilitätsfehler ohne Reparaturbedarf) gesendet. Die Umsetzung ist produktlinienspezifisch unterschiedlich. Nutzsignal wird permanent mit der Ungültigkeitskennung befüllt.), 7=Reserved_bne_BFE56DC998394BD9A8FED9E096CC9242_7 (QU_AVL_RPM_WHL_Reserved_bne_BFE56DC998394BD9A8FED9E096CC9242_7) (BNE original name: Reserved), 15=SignalUngueltig (QU_AVL_RPM_WHL_SignalUngueltig) (Kann nur vom Gateway gesetzt werden / BNE original name: Signal ungültig)  # Qualifier_Ist_Drehzahl_Rad / Qualifier_actual-value_RPM_wheel
  compu method RQ_CULI_SFY: 0=Keine_Strombegrenzung (RQ_CULI_SFY_Keine_Strombegrenzung), 10=Maximale_Strombegrenzung (RQ_CULI_SFY_Maximale_Strombegrenzung), 13=Reserviert_nicht_verfuegbar (RQ_CULI_SFY_Reserviert_nicht_verfuegbar) (Hinweis: Reserviert für funktionale Kennung Signal-Tag.), 14=Reserviert_Fehler (RQ_CULI_SFY_Reserviert_Fehler) (Hinweis: Reserviert für funktionale Kennung Signal-Tag.), 15=Signal_unbefuellt (RQ_CULI_SFY_Signal_unbefuellt) (Sendefunktion nicht in Betrieb)  # Anforderung_Strombegrenzung_Sicherheit / request_current-limitation_safety
  compu method SSV_IDENT: 0=REF_BAC4CAN_VIN (SSV_IDENT_REF_BAC4CAN_VIN), 1=DME1VIN (SSV_IDENT_DME1VIN) (BNE original name: DME1 VIN), 2=DME2VIN (SSV_IDENT_DME2VIN) (BNE original name: DME2 VIN), 3=RSEVIN (SSV_IDENT_RSEVIN) (Vorhalt / BNE original name: RSE VIN), 4=KAFASVIN (SSV_IDENT_KAFASVIN) (Vorhalt / BNE original name: KAFAS, VIN), 5=DSC_ModulVIN (SSV_IDENT_DSC_ModulVIN) (Vorhalt / BNE original name: DSC_Modul VIN), 6=VDPVIN (SSV_IDENT_VDPVIN) (Vorhalt / BNE original name: VDP VIN), 7=SASVIN (SSV_IDENT_SASVIN) (Vorhalt / BNE original name: SAS VIN), 8=NiViVIN (SSV_IDENT_NiViVIN) (Vorhalt / BNE original name: NiVi VIN), 9=HU_VIN (SSV_IDENT_HU_VIN) (Alle HUs), 10=EPS_VIN (SSV_IDENT_EPS_VIN) (Vorhalt), 11=REF_BAC4_FR_VIN (SSV_IDENT_REF_BAC4_FR_VIN), 19=MRR_VIN (SSV_IDENT_MRR_VIN), 20=ATM2_VIN (SSV_IDENT_ATM2_VIN), 21=Kombi_VIN (SSV_IDENT_Kombi_VIN), 255=SignalUngueltig (SSV_IDENT_SignalUngueltig) (BNE original name: Signal ungültig)  # SSV_Identifikation / SSV_identification
package /BMW/Boardnet/CodingDatatypes/DataConstraints
  range CRC8: phys 0..255  # Standartabsicherung Apllikations-CRC.
  range DIAG_ST_OBD: phys 0..63  # Diagnose_Status_OBD / diagnosis_status_OBD
  range I_SPEC_ARS: phys 0..252 A  # Strom_Vorgabe_ARS / current_specification_ARS
  range MAX_I_SPEC_SFY: phys 0..252 A  # Maximal_Strom_Vorgabe_Sicherheit / maximum_current_specification_safety
package /BMW/Boardnet/CodingDatatypes/SwBaseTypes
  base type ascii8: category=FIXED_LENGTH, base-type-size=8, base-type-encoding=ISO-8859-1, mem-alignment=8, native-declaration=unsigned char
package /BMW/Boardnet/Ecus/EcuComposition/EPSComposition
  composition sw component type EPSComponent
package /BMW/Boardnet/Pdus/ISignalGroups
  18 x i signal group:
    sigGroup_ACLNY_MASSCNTR: i-signal=[ACLNY_MASSCNTR/ACLNY_COG, ACLNY_MASSCNTR/ACLNY_COG_ERR_AMP, ACLNY_MASSCNTR/ACLNY_MASSCNTR_dummy_12_15, ACLNY_MASSCNTR/ALIV_ACLNY_COG, ACLNY_MASSCNTR/CRC_ACLNY_COG, ACLNY_MASSCNTR/QU_ACLNY_COG], system-signal-group=sigGroup_ACLNY_MASSCNTR
    sigGroup_AVL_FORC_GRD: i-signal=[AVL_FORC_GRD/ALIV_AVL_FORC_GRD, AVL_FORC_GRD/AVL_FORC_GRD, AVL_FORC_GRD/AVL_FORC_GRD_dummy_12_15, AVL_FORC_GRD/AVL_PWR_EL_EPS_COOD, AVL_FORC_GRD/CRC_AVL_FORC_GRD, AVL_FORC_GRD/QU_AVL_FORC_GRD], system-signal-group=sigGroup_AVL_FORC_GRD
    sigGroup_AVL_PO_EPS: i-signal=[AVL_PO_EPS/ALIV_AVL_PO_EPS, AVL_PO_EPS/AVL_PO_EPS, AVL_PO_EPS/AVL_PO_IDX_EPS, AVL_PO_EPS/CRC_AVL_PO_EPS, AVL_PO_EPS/IDX_TORQ_SEN, AVL_PO_EPS/OFFS_GRD_MID_EPS, AVL_PO_EPS/QU_AVL_PO_EPS, AVL_PO_EPS/UN_PO_EPS], system-signal-group=sigGroup_AVL_PO_EPS
    sigGroup_AVL_RPM_WHL: i-signal=[AVL_RPM_WHL/ALIV_AVL_RPM_WHL, AVL_RPM_WHL/AVL_RPM_WHL_FLH, AVL_RPM_WHL/AVL_RPM_WHL_FRH, AVL_RPM_WHL/AVL_RPM_WHL_RLH, AVL_RPM_WHL/AVL_RPM_WHL_RRH, AVL_RPM_WHL/AVL_RPM_WHL_dummy_12_15, AVL_RPM_WHL/CRC_AVL_RPM_WHL, AVL_RPM_WHL/QU_AVL_RPM_WHL_FLH, AVL_RPM_WHL/QU_AVL_RPM_WHL_FRH, AVL_RPM_WHL/QU_AVL_RPM_WHL_RLH, AVL_RPM_WHL/QU_AVL_RPM_WHL_RRH], system-signal-group=sigGroup_AVL_RPM_WHL
    sigGroup_AVL_STMOM_DV_ACT: i-signal=[AVL_STMOM_DV_ACT/ALIV_AVL_STMOM_DV_ACT, AVL_STMOM_DV_ACT/AVL_STMOM_DV_ACT, AVL_STMOM_DV_ACT/AVL_STMOM_DV_ACT_dummy_12_15, AVL_STMOM_DV_ACT/CRC_AVL_STMOM_DV_ACT, AVL_STMOM_DV_ACT/QU_AVL_STMOM_DV_ACT], system-signal-group=sigGroup_AVL_STMOM_DV_ACT
    sigGroup_CON_VEH: i-signal=[CON_VEH/ALIV_CON_VEH, CON_VEH/CON_VEH_dummy_56_63, CON_VEH/CRC_CON_VEH, CON_VEH/CTR_BS_PRTNT, CON_VEH/CTR_FKTN_PRTNT, CON_VEH/QU_ST_CON_VEH, CON_VEH/ST_CON_VEH], system-signal-group=sigGroup_CON_VEH
    sigGroup_DISP_CC_EPS: i-signal=[DISP_CC_EPS/ALIV_DISP_CC_EPS, DISP_CC_EPS/CHL_DISP_CC_EPS, DISP_CC_EPS/CRC_DISP_CC_EPS, DISP_CC_EPS/NO_CC_EPS, DISP_CC_EPS/ST_CC_EPS, DISP_CC_EPS/ST_IDC_CC_EPS, DISP_CC_EPS/TRANF_CC_EPS], system-signal-group=sigGroup_DISP_CC_EPS
    sigGroup_DT_EST: i-signal=[DT_EST/ALIV_DT_EST, DT_EST/AVL_I_ACT_EST, DT_EST/CRC_DT_EST, DT_EST/DT_EST_dummy_12_15, DT_EST/DT_EST_dummy_16_47, DT_EST/DT_EST_dummy_64_95, DT_EST/DT_EST_dummy_96_127, DT_EST/QU_AVL_I_ACT_EST, DT_EST/ST_CULI_EST], system-signal-group=sigGroup_DT_EST
    sigGroup_ENSU_SFY: i-signal=[ENSU_SFY/ALIV_ENSU_SFY, ENSU_SFY/CHL_ENSU_SFY, ENSU_SFY/CRC_ENSU_SFY, ENSU_SFY/ENSU_SFY_dummy_28_31, ENSU_SFY/ENSU_SFY_dummy_32_63, ENSU_SFY/QU_FN_ENSU_SFY, ENSU_SFY/RQ_CULI], system-signal-group=sigGroup_ENSU_SFY
    sigGroup_LIM_ENSU_DRDY_SFY: i-signal=[ALIV_LIM_ENSU_DRDY_SFY, CHL_LIM_ENSU_DRDY_SFY, CRC_LIM_ENSU_DRDY_SFY, LIM_ENSU_DRDY_SFY_dummy_40_63, MAX_I_SPEC_BRK_CSYS_SFY, MAX_I_SPEC_EST_SFY, RQ_CULI_BRK_CSYS_SFY, LIM_ENSU_DRDY_SFY/RQ_CULI_EST_SFY], system-signal-group=sigGroup_LIM_ENSU_DRDY_SFY
    sigGroup_OFFS_QUAD_EPS: i-signal=[OFFS_QUAD_EPS/ALIV_OFFS_QUAD_EPS, OFFS_QUAD_EPS/AVL_PO_IDX_ICM, OFFS_QUAD_EPS/CRC_OFFS_QUAD_EPS, OFFS_QUAD_EPS/OFFS_QUAD_RTR_EPS, OFFS_QUAD_EPS/ST_OFFS_QUAD_EPS], system-signal-group=sigGroup_OFFS_QUAD_EPS
    sigGroup_ST_EST: i-signal=[ST_EST/ALIV_ST_EST_FTAX, ST_EST/CRC_ST_EST_FTAX, ST_EST/QU_FN_EST, ST_EST/QU_FN_VIB_EPS, ST_EST/QU_SER_STMOM_DV_ACT, ST_EST/ST_EST_dummy_16_23], system-signal-group=sigGroup_ST_EST
    sigGroup_SU_EPS: i-signal=[SU_EPS/ALIV_SU_EPS, SU_EPS/CRC_SU_EPS, SU_EPS/SU_EPS_dummy_14_19, SU_EPS/SU_EPS_dummy_20_51, SU_EPS/TOT_STR_EPS, SU_EPS/UN_TOT_STR_EPS], system-signal-group=sigGroup_SU_EPS
    sigGroup_TAR_ESTP_VIRT_FTAX: i-signal=[TAR_ESTP_VIRT_FTAX/ACTVN_FN_ESTP_VIRT_FTAX, TAR_ESTP_VIRT_FTAX/ALIV_TAR_ESTP_VIRT_FTAX, TAR_ESTP_VIRT_FTAX/CRC_TAR_ESTP_VIRT_FTAX, TAR_ESTP_VIRT_FTAX/TAR_ESTP_VIRT_FTAX_dummy_12_31, TAR_ESTP_VIRT_FTAX/TAR_ESTP_VIRT_FTAX_dummy_36_63], system-signal-group=sigGroup_TAR_ESTP_VIRT_FTAX
    sigGroup_TAR_QTA_STRMOM_DV: i-signal=[TAR_QTA_STRMOM_DV/ALIV_TAR_QTA_STMOM_DV, TAR_QTA_STRMOM_DV/CRC_TAR_QTA_STMOM_DV, TAR_QTA_STRMOM_DV/CTR_DEAC_EPS_FNS, TAR_QTA_STRMOM_DV/FACT_ASS_STMOM_FTAX, TAR_QTA_STRMOM_DV/FACT_CTRR_STMOM_FTAX, TAR_QTA_STRMOM_DV/FACT_DMPNG_STMOM_FTAX, TAR_QTA_STRMOM_DV/QU_TAR_FACT_STMOM_FTAX, TAR_QTA_STRMOM_DV/QU_TAR_QTA_STMOM_DV, TAR_QTA_STRMOM_DV/TAR_QTA_STMOM_DV, TAR_QTA_STRMOM_DV/TAR_QTA_STRMOM_DV_dummy_12_15], system-signal-group=sigGroup_TAR_QTA_STRMOM_DV
    sigGroup_TAR_STMOM_DV_ACT: i-signal=[TAR_STMOM_DV_ACT/ALIV_TAR_STMOM_DV_ACT, TAR_STMOM_DV_ACT/CRC_TAR_STMOM_DV_ACT, TAR_STMOM_DV_ACT/FACT_DMPNG_ADDON_STMOM_FTAX, TAR_STMOM_DV_ACT/QU_TAR_DMPNG_ADDON_STMOM_FTAX, TAR_STMOM_DV_ACT/QU_TAR_STMOM_DV_ACT, TAR_STMOM_DV_ACT/TAR_STMOM_DV_ACT, TAR_STMOM_DV_ACT/TAR_STMOM_DV_ACT_dummy_12_15, TAR_STMOM_DV_ACT/TAR_STMOM_DV_ACT_dummy_32_51], system-signal-group=sigGroup_TAR_STMOM_DV_ACT
    sigGroup_VYAW_VEH: i-signal=[VYAW_VEH/ALIV_VYAW_VEH, VYAW_VEH/CRC_VYAW_VEH, VYAW_VEH/QU_VYAW_VEH, VYAW_VEH/VYAW_VEH, VYAW_VEH/VYAW_VEH_ERR_AMP, VYAW_VEH/VYAW_VEH_dummy_12_15], system-signal-group=sigGroup_VYAW_VEH
    sigGroup_V_VEH: i-signal=[V_VEH/ALIV_V_VEH, V_VEH/CRC_V_VEH, V_VEH/DVCO_VEH, V_VEH/QU_V_VEH_COG, V_VEH/ST_V_VEH_NSS, V_VEH/V_VEH_COG, V_VEH/V_VEH_dummy_39_39], system-signal-group=sigGroup_V_VEH
package /BMW/Boardnet/Pdus/PDUs
  pdu ANFRAGE: length=8, minimum-delay=0.5, transmission-mode-true-timing=event-controlled-timing=number-of-repetitions=0, unused-bit-pattern=255  # Anfrage / Inquiry | Diese PDU löst die bis einschließlich SP2015 gültige Version der gleichnamigen PDU ab. Ab SP2018 darf nur noch diese Version der PDU verwendet werden. Mit dem Anfrage-Dienst kann eine Nachricht, die als anfragbar definiert ist, angefragt werden.
    signal ANFRAGE_ID2: start 0, 8 bit, little-endian, init-value=SWITCH_CODE:1, base-type=uint8, transfer-property=PENDING, to EPS
    signal ID_FN_INQY: start 8, 16 bit, little-endian, base-type=uint16, invalid-value=value_65535Dot0:65535, compu {41216=BedienungTastenEntertainment (ID_FN_INQY_BedienungTastenEntertainment) (BNE original name: Bedienung Tasten Entertainment), 62976=SteuerungAussenspiegel (ID_FN_INQY_SteuerungAussenspiegel) (BNE original name: Steuerung Außenspiegel), 57857=SicherFahrgestellnummer (ID_FN_INQY_SicherFahrgestellnummer) (BNE original name: Sicher Fahrgestellnummer), 9730=Regensensor_Wischergeschwindigkeit (ID_FN_INQY_Regensensor_Wischergeschwindigkeit) (BNE original name: Regensensor-Wischergeschwindigkeit), 14850=StatusFunkschluessel (ID_FN_INQY_StatusFunkschluessel) (BNE original name: Status Funkschlüssel), 26370=BedienungTastgeberBedienelementFront (ID_FN_INQY_BedienungTastgeberBedienelementFront) (BNE original name: Bedienung Tastgeber Bedienelement Front), 32258=StatusVerdeckCabrio (ID_FN_INQY_StatusVerdeckCabrio) (Wird ab BN2020 nur noch von HMI verwendet / BNE original name: Status Verdeck Cabrio), 36866=StatusSchluesselSuche (ID_FN_INQY_StatusSchluesselSuche) (BNE original name: Status Schlüssel Suche), 58882=StatusKlimaLuftverteilungFA (ID_FN_INQY_StatusKlimaLuftverteilungFA) (BNE original name: Status Klima Luftverteilung FA), 59906=StatusKlimaLuftverteilungBF (ID_FN_INQY_StatusKlimaLuftverteilungBF) (BNE original name: Status Klima Luftverteilung BF), 60418=StatusKlimaSHSlashZHZusatzwasserpumpe (ID_FN_INQY_StatusKlimaSHSlashZHZusatzwasserpumpe) (BNE original name: Status Klima SH/ZH Zusatzwasserpumpe), 60930=StatusKlimaZusatzprogramme (ID_FN_INQY_StatusKlimaZusatzprogramme) (Wird ab BN2020 nur noch von HMI verwendet / BNE original name: Status Klima Zusatzprogramme), 61442=StatusKlimaStandfunktionen (ID_FN_INQY_StatusKlimaStandfunktionen) (BNE original name: Status Klima Standfunktionen), 63234=EinheitenBN2020 (ID_FN_INQY_EinheitenBN2020) (BNE original name: Einheiten BN2020), 63490=UhrzeitSlashDatum (ID_FN_INQY_UhrzeitSlashDatum) (BNE original name: Uhrzeit/Datum), 3843=StatusServiceCallTeleX (ID_FN_INQY_StatusServiceCallTeleX) (BNE original name: Status Service Call TeleX), 4867=StatusServiceCallTeleservice (ID_FN_INQY_StatusServiceCallTeleservice) (BNE original name: Status Service Call Teleservice), 12803=VerbrauchInformationDaten (ID_FN_INQY_VerbrauchInformationDaten) (BNE original name: Verbrauch Information Daten), 13827=AnzeigeCheckcontrol_Meldung_Rolle_ (ID_FN_INQY_AnzeigeCheckcontrol_Meldung_Rolle_) (BNE original name: Anzeige Checkcontrol-Meldung (Rolle)), 14851=StatusMonitorFront (ID_FN_INQY_StatusMonitorFront) ((E60, RR01) Wird ab BN2020 nur noch von HMI verwendet / (E60, RR01) / BNE original name: Status Monitor Front), 16643=StatusKartendaten (ID_FN_INQY_StatusKartendaten) (BNE original name: Status Kartendaten), 23555=StatusBordcomputerBN2020 (ID_FN_INQY_StatusBordcomputerBN2020) ((E60) / BNE original name: Status Bordcomputer BN2020), 24579=DatenBordcomputer_Fahrtbeginn_ (ID_FN_INQY_DatenBordcomputer_Fahrtbeginn_) ((E60) / BNE original name: Daten Bordcomputer (Fahrtbeginn)), 32771=Fahrgestellnummer (ID_FN_INQY_Fahrgestellnummer), 33027=ElektronischerMotoroelmessstab (ID_FN_INQY_ElektronischerMotoroelmessstab) (BNE original name: Elektronischer Motorölmessstab), 34819=Fahrzeugtyp (ID_FN_INQY_Fahrzeugtyp), 38147=CodierungPowermanagement (ID_FN_INQY_CodierungPowermanagement) (BNE original name: Codierung Powermanagement), 40451=Bedienung_Uhrzeit_Datum (ID_FN_INQY_Bedienung_Uhrzeit_Datum), 43523=Bedienung_Uhrzeit_Datum_UTC (ID_FN_INQY_Bedienung_Uhrzeit_Datum_UTC), 43779=Bedienung_Datum_Winterzeit_Sommerzeit (ID_FN_INQY_Bedienung_Datum_Winterzeit_Sommerzeit), 46595=PositionFensterheberFAT (ID_FN_INQY_PositionFensterheberFAT) (ACHTUNG: Hier wird der CAN-Identifier der Nachricht angegeben, auch wenn die Nachricht beim E60 vom SI-Bus kommt. Die E60-Türelektronik FAT am SI-Bus müssen auf diese Codierung reagieren und die Nachricht Position Fensterheber FAT auf Anfrage raussenden. / ATTENTION:The CAN identifier of the message cannot be given here, even if the message comes from the SI bus with E60. The E60 door electronics DRD on the SI bus must react to this coding and send out the position of window regulator DRD message on request. / BNE original name: Position Fensterheber FAT), 46851=PositionFensterheberFATH (ID_FN_INQY_PositionFensterheberFATH) (BNE original name: Position Fensterheber FATH), 47107=PositionFensterheberBFT (ID_FN_INQY_PositionFensterheberBFT) (ACHTUNG: Hier wird der CAN-Identifier der Nachricht angegeben, auch wenn die Nachricht beim E60 vom SI-Bus kommt. Die E60-Türelektronik BFT am SI-Bus müssen auf diese Codierung reagieren und die Nachricht Position Fensterheber BFT auf Anfrage raussenden. / ATTENTION:The CAN identifier of the message is given here, even if the message comes from the SI bus with E60. The E60 door electronics PSD on the SI bus must react to this coding and send out the position of electric windows PSD message on request. / BNE original name: Position Fensterheber BFT), 47363=PositionFensterheberBFTH (ID_FN_INQY_PositionFensterheberBFTH) (BNE original name: Position Fensterheber BFTH), 47619=PositionSHD (ID_FN_INQY_PositionSHD) (BNE original name: Position SHD), 48131=PositionFensterheberSicherheitsfahrzeug (ID_FN_INQY_PositionFensterheberSicherheitsfahrzeug) (BNE original name: Position Fensterheber Sicherheitsfahrzeug), 48899=PositionFensterheberHeckscheibe (ID_FN_INQY_PositionFensterheberHeckscheibe) (BNE original name: Position Fensterheber Heckscheibe), 49155=KonfigurationFAS (ID_FN_INQY_KonfigurationFAS) (BNE original name: Konfiguration FAS), 49411=KonfigurationBFS (ID_FN_INQY_KonfigurationBFS) (BNE original name: Konfiguration BFS), 49667=KonfigurationFASH (ID_FN_INQY_KonfigurationFASH) (BNE original name: Konfiguration FASH), 49923=KonfigurationBFSH (ID_FN_INQY_KonfigurationBFSH) (BNE original name: Konfiguration BFSH), 53251=StatusSpurverlassenswarnsystemCKM (ID_FN_INQY_StatusSpurverlassenswarnsystemCKM) (BNE original name: Status Spurverlassenswarnsystem CKM), 54531=StatusZentralverriegelungCKM (ID_FN_INQY_StatusZentralverriegelungCKM) (BNE original name: Status Zentralverriegelung CKM), 55043=StatusDWACKM (ID_FN_INQY_StatusDWACKM) (BNE original name: Status DWA CKM), 56067=StatusMemorypositionenCKM (ID_FN_INQY_StatusMemorypositionenCKM) (BNE original name: Status Memorypositionen CKM), 56579=StatusLichtCKM (ID_FN_INQY_StatusLichtCKM) (BNE original name: Status Licht CKM), 57603=StatusALCCKM (ID_FN_INQY_StatusALCCKM) (BNE original name: Status ALC CKM), 58115=StatusHeckklappeCKM (ID_FN_INQY_StatusHeckklappeCKM) (BNE original name: Status Heckklappe CKM), 60163=GrenzwerteSchwenkLinks (ID_FN_INQY_GrenzwerteSchwenkLinks) (BNE original name: Grenzwerte Schwenk Links), 60419=GrenzwerteSchwenkRechts (ID_FN_INQY_GrenzwerteSchwenkRechts) (BNE original name: Grenzwerte Schwenk Rechts), 61699=StatusLichtErweitertCKM (ID_FN_INQY_StatusLichtErweitertCKM) (BNE original name: Status Licht Erweitert CKM), 9731=WirkungsgradInformationData (ID_FN_INQY_WirkungsgradInformationData) (BNE original name: Wirkungsgrad Information Data), 10243=RelativzeitBN2020 (ID_FN_INQY_RelativzeitBN2020) (BNE original name: Relativzeit BN2020), 3588=GPS_Datum_CAN (ID_FN_INQY_GPS_Datum_CAN), 3844=GPS_Uhrzeit_CAN (ID_FN_INQY_GPS_Uhrzeit_CAN), 6660=StatusKonfigurationKombi4 (ID_FN_INQY_StatusKonfigurationKombi4) (BNE original name: Status Konfiguration Kombi 4), 9220=StatusKonfigurationKombi (ID_FN_INQY_StatusKonfigurationKombi) (BNE original name: Status Konfiguration Kombi), 9988=KonfigurationDSC (ID_FN_INQY_KonfigurationDSC) (BNE original name: Konfiguration DSC), 11780=StatusM_Drive2 (ID_FN_INQY_StatusM_Drive2) (BNE original name: Status M-Drive 2), 13316=KonfigurationEPS (ID_FN_INQY_KonfigurationEPS) (BNE original name: Konfiguration EPS), 13572=MessungMotoroel (ID_FN_INQY_MessungMotoroel) (BNE original name: Messung Motoröl), 16132=IdentifikationsnummerSensorcluster (ID_FN_INQY_IdentifikationsnummerSensorcluster) (BNE original name: Identifikationsnummer Sensorcluster), 16642=Status_Hindernis_Tuer (ID_FN_INQY_Status_Hindernis_Tuer), 65535=Signal_unbefuellt (ID_FN_INQY_Signal_unbefuellt), 65533=Reserviert_nicht_verfuegbar (ID_FN_INQY_Reserviert_nicht_verfuegbar) (Hinweis: Reserviert für funktionale Kennung Signal-Tag "Funktionsschnittstelle_ist_nicht_verfuegbar"), 65534=Reserviert_Fehler (ID_FN_INQY_Reserviert_Fehler) (Hinweis: Reserviert für funktionale Kennung Signal-Tag "Funktion_meldet_Fehler")} "ID_Funktion_Anfrage / ID_function_inquiry | Enthält den Identifier der angefragten Nachricht. Es sind nur die Identifier erlaubt, die als anfragbare Nachrichten definiert sind.", to EPS  # ID_Funktion_Anfrage / ID_function_inquiry | LogicalInterface:BMW.INFRASTRUCTURE.COMMUNICATION.InquiryService[external]@Infrastruktur; Dieses Signal löst die bis einschließlich SP2015 gültige Version des gleichnamigen Signales ab. Ab SP2018 darf nur noch diese Version des Signals verwendet werden. Damit wird die in der alten Signalversion existierende Ausnahme bezüglich der Byteorder aufgelöst. Die Darstellung der Signal-Inhalte auf dem Bus wird dadurch jedoch nicht verändert – um dies zu erreichen wurden High-Byte und Low-Byte der Kodierungen vertauscht. Achtung: Sollte es sich sender- oder empfängerseitig um ein reines SP2015-Gleichteil handeln, das demnach die Versendung oder den Empfang des Signals ID_Funktion_Anfrage unverändert zu SP2015 umsetzt, so ist die hier spezifizierte Version des Signals ungültig! Für diese Gleichteile ist die für SP2015 spezifizierte Version dieses Signals gültig. Dieses Signal enthält in der Regel den 11-Bit CAN-Identifier der angefragten Nachricht. Es kann allerdings Abweichungen von dieser Regel geben, z.B. - im Fall von Zuordnungen mehrerer anfragbarer Frames zu einer CAN-ID - im Fall busspezifischer unterschiedlicher CAN-IDs des angefragten Frames - im Fall von Anfragen auf Nicht-CAN Bussen (z.B. FlexRay) - im Fall von 29-Bit CAN-IDs der angefragten Frames Es sind nur die Codierungen erlaubt, zu denen anfragbare PDUs definiert sind. / This signal contains the identifier of the message inquired. Only the identifiers are allowed which are defined as addressable messages. N.B. As regards byte orderings, this signal constitutes an exception because the inquired identifier must be transmitted in Engineola format. In the definite case this means that Byte 1 contains the high byte and Byte 2 the low byte of the desired identifiers [Byte 1, Bit 0: 2^8, Byte 1, Bit 7: 2^15 (= MSEC.B) and Byte 2, Bit 0: 2^0 (= LSB), Byte 2, Bit 7: 2^7]
  pdu DBG_EPS_BS_MOD_58_BYTE: length=58, transmission-mode-true-timing=cyclic-timing=time-period={tolerance=absolute-tolerance=0.004, value=0.02}, unused-bit-pattern=255  # Debug EPS Modus Basis 58 Byte | Diese PDU enthält die 57-Byte langen Debug Information. Die Signale in dieser PDU können durch den Fachbereich eigenständig angepasst werden.
    signal DBG_EPS_BS_MOD_58_BYTE_ID2: start 0, 8 bit, little-endian, init-value=SWITCH_CODE:1, base-type=uint8, transfer-property=PENDING
    signal DBG_EPS_MOD_BS_58_BYTE: start 8, 8 bit, little-endian, base-type=uint8, compu {identical}, range phys 0..255  # Debug_EPS_Modus_Basis_58_Byte / debug_EPS_mode_base_58_byte | LogicalInterface:BMW.INFRASTRUCTURE.DIAGNOSIS.Debug[internal]@Infrastruktur; Dummy-Signal. Kann beliebig geändert werden.
  pdu DBG_EPS_MOD_EXT_120_BYTE: length=58, transmission-mode-true-timing=cyclic-timing=time-period={tolerance=absolute-tolerance=0.001, value=0.005}, unused-bit-pattern=255  # Debug EPS Modus Erweitert 120 Byte | Diese PDU enthält die 119-Byte langen Debug Information. Bei Verwendung dieses Modes muss die Frame Länge vom Fachbereich auf 120-Bytes angepasst werden. Die Signale in dieser PDU können durch den Fachbereich eigenständig angepasst werden.
    signal DBG_EPS_MOD_EXT_120_BYTE: start 8, 8 bit, little-endian, base-type=uint8, compu {identical}, range phys 0..255  # Debug_EPS_Modus_Erweitert_120_Byte / debug_EPS_mode_extended_120_byte | LogicalInterface:BMW.INFRASTRUCTURE.DIAGNOSIS.Debug[internal]@Infrastruktur; Dummy-Signal. Kann beliebig geändert werden.
    signal DBG_EPS_MOD_EXT_120_BYTE_ID2: start 0, 8 bit, little-endian, init-value=SWITCH_CODE:2, base-type=uint8, transfer-property=PENDING
  pdu RQ_STG_EFAN:  # Anforderung Wärmemanagement / Request Stage Electric-Fan
    length=8
    transmission-mode-true-timing=cyclic-timing={time-period={tolerance=absolute-tolerance=0.2, value=1}, "Um sicherzustellen, dass das Ende der zyklischen Versendung erkannt wird, muss die Versendung der Stoppnachricht (Signal Anforderung_Steuerung_Elektrolüfter = 0) insgesamt 3-mal mit einem Wiederholzyklus von t=160 ms erfolgen (Details in der Spezifikation: Erweiterung der ereignisgesteuerten Auslösebedingungen). Zusätzlich erfolgt eine zyklische Versendung der Nachricht, wenn die Signale Temperatur_Komponente_Wärmemanagement und ID_Temperatur_Komponente_Wärmemanagement befüllt sind."}
    unused-bit-pattern=255
    signal ID_FN_RQ_STG_EFAN: start 8, 8 bit, little-endian, base-type=uint8, invalid-value=value_255Dot0:255, compu {1=AFS_Anforderung (ID_FN_RQ_STG_EFAN_AFS_Anforderung) (Diese Nachricht darf vom AFS ausschließlich zum Bauteilschutz im Notfall versandt werden! Anforderung wird vom E6x/PL2/PL4 AFS nicht mehr versendet. / BNE original name: AFS-Anforderung), 2=EPS_Anforderung (ID_FN_RQ_STG_EFAN_EPS_Anforderung) (Diese Nachricht darf vom EPS ausschließlich zum Bauteilschutz im Notfall versandt werden! / BNE original name: EPS-Anforderung), 3=DSC_Anforderung (ID_FN_RQ_STG_EFAN_DSC_Anforderung) (Diese Nachricht darf vom DSC ausschließlich zum Bauteilschutz im Notfall versandt werden! / BNE original name: DSC-Anforderung), 4=Servotronic_Anforderung (ID_FN_RQ_STG_EFAN_Servotronic_Anforderung) (Diese Kodierung wird _nicht_ in den Baureihen L1 bis L5 verwendet. Diese Nachricht darf ausschließlich zum Bauteilschutz im Notfall versandt werden! / BNE original name: Servotronic-Anforderung), 255=SignalUngueltig (ID_FN_RQ_STG_EFAN_SignalUngueltig) (BNE original name: Signal ungültig)} "ID_Funktion_Anforderung_Stufe_Elektrolüfter / ID_function_request_stage_electric-fan | Automatisch generiert (Migration 2004-10-30)"  # ID_Funktion_Anforderung_Stufe_Elektrolüfter / ID_function_request_stage_electric-fan | LogicalInterface:BMW.POWERTRAIN.ENGINE.COMBUSTION.HeatManagement[internal]@Fahren; Dieses Signal gibt den Anforderer der gewünschten Elektrolüfterstufe an.
    signal ID_TEMP_CPO_HET_MNG: start 20, 4 bit, little-endian, base-type=uint8, invalid-value=value_15Dot0:15, compu {1=EPS_Motortemperatur (ID_TEMP_CPO_HET_MNG_EPS_Motortemperatur) (BNE original name: EPS-Motortemperatur), 13=Reserviert (ID_TEMP_CPO_HET_MNG_Reserviert) (Hinweis: Reserviert für funktionale Kennung Signal-Tag.), 14=Reserviert_bne_FCE0E84AD43C48B79F8D9B411125541C_14 (ID_TEMP_CPO_HET_MNG_Reserviert_bne_FCE0E84AD43C48B79F8D9B411125541C_14) (Hinweis: Reserviert für funktionale Kennung Signal-Tag. / BNE original name: Reserviert), 15=Signal_unbefuellt (ID_TEMP_CPO_HET_MNG_Signal_unbefuellt) (Sendefunktion nicht in Betrieb)} "ID_Temperatur_Komponente_Wärme_Management / ID_temperature_component_heat_management"  # ID_Temperatur_Komponente_Wärme_Management / ID_temperature_component_heat_management | LogicalInterface:BMW.POWERTRAIN.ENGINE.COMBUSTION.HeatManagement[internal]@Fahren; Dieses Signal gibt die Komponente für das Temperatursignal für das Motorwärmemanagement an. Dieses Signal wird in 444, F15-F16, F25 und F25_ab_PU12-07 nicht ausgewertet.
    signal RQ_STG_EFAN: start 16, 4 bit, little-endian, base-type=uint8, invalid-value=value_15Dot0:15, compu {0=AUS (RQ_STG_EFAN_AUS), 1=Stufe (RQ_STG_EFAN_Stufe), 15=SignalUngueltig (RQ_STG_EFAN_SignalUngueltig) (BNE original name: Signal ungültig)} "Anforderung_Stufe_Elektrolüfter / request_stage_electric-fan | Automatisch generiert (Migration 2004-10-30)"  # Anforderung_Stufe_Elektrolüfter / request_stage_electric-fan | LogicalInterface:BMW.POWERTRAIN.ENGINE.COMBUSTION.HeatManagement[internal]@Fahren; Die Stufen werden als Luftmassenstrom interpretiert. Die Stufe 14 entspricht der maximalen Luftmassenstromanforderung.
    signal RQ_STG_EFAN_ID2: start 0, 8 bit, little-endian, init-value=SWITCH_CODE:21, base-type=uint8, transfer-property=PENDING
    signal TEMP_CPO_HET_MNG: start 24, 8 bit, little-endian, base-type=uint8, invalid-value=value_255Dot0:255, compu {phys=raw-48 for raw 48..300, 253=Reserviert (TEMP_CPO_HET_MNG_Reserviert) (Hinweis: Reserviert für funktionale Kennung Signal-Tag.), 254=Reserviert_bne_13E59F6816364760A116813207E86FA4_254 (TEMP_CPO_HET_MNG_Reserviert_bne_13E59F6816364760A116813207E86FA4_254) (Hinweis: Reserviert für funktionale Kennung Signal-Tag. / BNE original name: Reserviert), 255=Signal_unbefuellt (TEMP_CPO_HET_MNG_Signal_unbefuellt) (Sendefunktion nicht in Betrieb); unit DegCgrd} "Temperatur_Komponente_Wärme_Management / temperature_component_heat_management", range phys 0..252 DegCgrd "Temperatur_Komponente_Wärme_Management / temperature_component_heat_management"  # Temperatur_Komponente_Wärme_Management / temperature_component_heat_management | LogicalInterface:BMW.POWERTRAIN.ENGINE.COMBUSTION.HeatManagement[internal]@Fahren; Komponententemperatur für das Motorwärmemanagement Dieses Signal wird in 444, F15-F16, F25 und F25_ab_PU12-07 nicht ausgewertet.
  pdu SECU_CHAL: length=8, minimum-delay=0.05, transmission-mode-true-timing=event-controlled-timing=number-of-repetitions=0, unused-bit-pattern=255  # Sicher Challenge | $(AUTOSAR; SIGNALGROUP)
    signal SECU_CHAL: start 24, 40 bit, little-endian, base-type=uint64, invalid-value=value_1Dot099511627775E12:1099511627775, compu {identical}, range phys 0..1099511627775  # Sicher_Challenge / secure_challenge | LogicalInterface:BMW.INFRASTRUCTURE.COMMUNICATION.SecureChallengeResponse[internal]@Infrastruktur;
    signal SECU_CHAL_ID2: start 0, 8 bit, little-endian, init-value=SWITCH_CODE:248, base-type=uint8, transfer-property=PENDING
    signal SSS_IDENT_CHAL: start 16, 8 bit, little-endian, base-type=uint8, invalid-value=value_255Dot0:255, compu {0=ZGWVIN (SSS_IDENT_ZGWVIN) (BNE original name: ZGW VIN), 255=SignalUngueltig (SSS_IDENT_SignalUngueltig) (BNE original name: Signal ungültig)} "SSS_Identifikation / SSS_identification"  # SSS_Identifikation_Challenge / SSS_identification_challenge | LogicalInterface:BMW.INFRASTRUCTURE.COMMUNICATION.SecureChallengeResponse[internal]@Infrastruktur;
    signal SSV_IDENT_CHAL: start 8, 8 bit, little-endian, base-type=uint8, invalid-value=value_255Dot0:255, compu-method=CompuMethodsForBoardnet/SSV_IDENT  # SSV_Identifikation_Challenge / SSV_identification_challenge | LogicalInterface:BMW.INFRASTRUCTURE.COMMUNICATION.SecureChallengeResponse[internal]@Infrastruktur;
  pdu SECU_RESP: length=8, minimum-delay=0.05, transmission-mode-true-timing=event-controlled-timing=number-of-repetitions=0, unused-bit-pattern=255  # Sicher Response | $(AUTOSAR; SIGNALGROUP)
    signal COU_BS_RESP: start 16, 24 bit, little-endian, base-type=uint32, invalid-value=value_1Dot6777215E7:16777215, compu {identical}, range phys 0..16777214, to EPS  # Zähler_Basis_Response / counter_base_response | LogicalInterface:BMW.INFRASTRUCTURE.COMMUNICATION.SecureChallengeResponse[internal]@Infrastruktur;
    signal SECU_RESP_ID2: start 0, 8 bit, little-endian, init-value=SWITCH_CODE:247, base-type=uint8, transfer-property=PENDING, to EPS
    signal SSV_IDENT_RESP: start 8, 8 bit, little-endian, base-type=uint8, invalid-value=value_255Dot0:255, compu-method=CompuMethodsForBoardnet/SSV_IDENT, to EPS  # SSV_Identifikation_Response / SSV_identification_response | LogicalInterface:BMW.INFRASTRUCTURE.COMMUNICATION.SecureChallengeResponse[internal]@Infrastruktur;
    signal STU_RESP: start 40, 24 bit, little-endian, base-type=uint32, invalid-value=value_1Dot6777215E7:16777215, compu {identical}, range phys 0..16777215, to EPS  # Signatur_Response / signature_response | LogicalInterface:BMW.INFRASTRUCTURE.COMMUNICATION.SecureChallengeResponse[internal]@Infrastruktur;
package /BMW/SystemComposition
  composition sw component type SystemComponent
    component EPSInstance: type=EPSComponent
package /BMW/Units
  5 x unit, all with offset-si-to-unit=0:
    ampere: display-name=A, factor-si-to-unit=1, physical-dimension=ampere
    degree_per_second: display-name=°/s, factor-si-to-unit=3.141592653589793, physical-dimension=degree_per_second
    kilometer_per_hour: display-name=km/h, factor-si-to-unit=1000, physical-dimension=kilometer_per_hour
    kilonewton: display-name=kN, factor-si-to-unit=1000, physical-dimension=kilonewton
    kilowatt: display-name=kW, factor-si-to-unit=1000, physical-dimension=kilowatt
package /BMW/Units/PhysicalDimensions
  5 x physical dimension, all with temperature-exp=0, molar-amount-exp=0, luminous-intensity-exp=0:
    ampere: length-exp=0, mass-exp=0, time-exp=0, current-exp=1
    degree_per_second: length-exp=0, mass-exp=0, time-exp=-1, current-exp=0
    kilometer_per_hour: length-exp=0, mass-exp=0, time-exp=-1, current-exp=0
    kilonewton: length-exp=1, mass-exp=1, time-exp=-2, current-exp=0
    kilowatt: length-exp=2, mass-exp=1, time-exp=-3, current-exp=0
package /Systems
  system EPS: pnc-vector-length=6, pnc-vector-offset=2, system-version=0.0.1
    system mapping Systems_SwcToEcuMapping
      sw-mappings:
        swc to ecu mapping EPSInstance: component=SystemComponentPrototype.EPSInstance, ecu-instance=EPS
    root-software-compositions:
      root sw composition prototype SystemComponentPrototype: software-composition=SystemComponent
package /Systems/EndToEndProtections
  end to end protection set EndToEndProtectionSet
    18 x end to end protection:
      endToEndProt_ACLNY_MASSCNTR: end-to-end-profile={category=PROFILE_01, data-ids=31, data-id-mode=0, data-length=48, max-delta-counter-init=14, crc-offset=0, counter-offset=8}, end-to-end-protection-i-signal-i-pdu{data-offset=0, i-signal-group=sigGroup_ACLNY_MASSCNTR, i-signal-i-pdu=PDUs/ACLNY_MASSCNTR}
      endToEndProt_AVL_FORC_GRD: end-to-end-profile={category=PROFILE_01, data-ids=190, data-id-mode=0, data-length=40, max-delta-counter-init=14, crc-offset=0, counter-offset=8}, end-to-end-protection-i-signal-i-pdu{data-offset=0, i-signal-group=sigGroup_AVL_FORC_GRD, i-signal-i-pdu=PDUs/AVL_FORC_GRD}
      endToEndProt_AVL_PO_EPS: end-to-end-profile={category=PROFILE_01, data-ids=186, data-id-mode=0, data-length=64, max-delta-counter-init=14, crc-offset=0, counter-offset=8}, end-to-end-protection-i-signal-i-pdu{data-offset=0, i-signal-group=sigGroup_AVL_PO_EPS, i-signal-i-pdu=PDUs/AVL_PO_EPS}
      endToEndProt_AVL_RPM_WHL: end-to-end-profile={category=PROFILE_01, data-ids=17, data-id-mode=0, data-length=96, max-delta-counter-init=14, crc-offset=0, counter-offset=8}, end-to-end-protection-i-signal-i-pdu{data-offset=0, i-signal-group=sigGroup_AVL_RPM_WHL, i-signal-i-pdu=PDUs/AVL_RPM_WHL}
      endToEndProt_AVL_STMOM_DV_ACT: end-to-end-profile={category=PROFILE_01, data-ids=108, data-id-mode=0, data-length=32, max-delta-counter-init=14, crc-offset=0, counter-offset=8}, end-to-end-protection-i-signal-i-pdu{data-offset=0, i-signal-group=sigGroup_AVL_STMOM_DV_ACT, i-signal-i-pdu=PDUs/AVL_STMOM_DV_ACT}
      endToEndProt_CON_VEH: end-to-end-profile={category=PROFILE_01, data-ids=197, data-id-mode=0, data-length=64, max-delta-counter-init=14, crc-offset=0, counter-offset=8}, end-to-end-protection-i-signal-i-pdu{data-offset=0, i-signal-group=sigGroup_CON_VEH, i-signal-i-pdu=PDUs/CON_VEH}
      endToEndProt_DISP_CC_EPS: end-to-end-profile={category=PROFILE_01, data-ids=3148, data-id-mode=3, data-length=40, max-delta-counter-init=14, crc-offset=0, counter-offset=8, data-id-nibble-offset=12}, end-to-end-protection-i-signal-i-pdu{data-offset=0, i-signal-group=sigGroup_DISP_CC_EPS, i-signal-i-pdu=PDUs/DISP_CC_EPS}
      endToEndProt_DT_EST: end-to-end-profile={category=PROFILE_01, data-ids=230, data-id-mode=0, data-length=128, max-delta-counter-init=14, crc-offset=0, counter-offset=8}, end-to-end-protection-i-signal-i-pdu{data-offset=0, i-signal-group=sigGroup_DT_EST, i-signal-i-pdu=PDUs/DT_EST}
      endToEndProt_ENSU_SFY: end-to-end-profile={category=PROFILE_01, data-ids=628, data-id-mode=3, data-length=64, max-delta-counter-init=14, crc-offset=0, counter-offset=8, data-id-nibble-offset=12}, end-to-end-protection-i-signal-i-pdu{data-offset=0, i-signal-group=sigGroup_ENSU_SFY, i-signal-i-pdu=PDUs/ENSU_SFY}
      endToEndProt_LIM_ENSU_DRDY_SFY: end-to-end-profile={category=PROFILE_01, data-ids=372, data-id-mode=3, data-length=64, max-delta-counter-init=14, crc-offset=0, counter-offset=8, data-id-nibble-offset=12}, end-to-end-protection-i-signal-i-pdu{data-offset=0, i-signal-group=sigGroup_LIM_ENSU_DRDY_SFY, i-signal-i-pdu=LIM_ENSU_DRDY_SFY}
      endToEndProt_OFFS_QUAD_EPS: end-to-end-profile={category=PROFILE_01, data-ids=229, data-id-mode=0, data-length=40, max-delta-counter-init=14, crc-offset=0, counter-offset=8}, end-to-end-protection-i-signal-i-pdu{data-offset=0, i-signal-group=sigGroup_OFFS_QUAD_EPS, i-signal-i-pdu=PDUs/OFFS_QUAD_EPS}
      endToEndProt_ST_EST: end-to-end-profile={category=PROFILE_01, data-ids=112, data-id-mode=0, data-length=40, max-delta-counter-init=14, crc-offset=0, counter-offset=8}, end-to-end-protection-i-signal-i-pdu{data-offset=0, i-signal-group=sigGroup_ST_EST, i-signal-i-pdu=PDUs/ST_EST}
      endToEndProt_SU_EPS: end-to-end-profile={category=PROFILE_01, data-ids=131, data-id-mode=0, data-length=64, max-delta-counter-init=14, crc-offset=56, counter-offset=52}, end-to-end-protection-i-signal-i-pdu{data-offset=0, i-signal-group=sigGroup_SU_EPS, i-signal-i-pdu=PDUs/SU_EPS}
      endToEndProt_TAR_ESTP_VIRT_FTAX: end-to-end-profile={category=PROFILE_01, data-ids=52, data-id-mode=0, data-length=64, max-delta-counter-init=14, crc-offset=0, counter-offset=8}, end-to-end-protection-i-signal-i-pdu{data-offset=0, i-signal-group=sigGroup_TAR_ESTP_VIRT_FTAX, i-signal-i-pdu=PDUs/TAR_ESTP_VIRT_FTAX}
      endToEndProt_TAR_QTA_STRMOM_DV: end-to-end-profile={category=PROFILE_01, data-ids=109, data-id-mode=0, data-length=64, max-delta-counter-init=14, crc-offset=0, counter-offset=8}, end-to-end-protection-i-signal-i-pdu{data-offset=0, i-signal-group=sigGroup_TAR_QTA_STRMOM_DV, i-signal-i-pdu=PDUs/TAR_QTA_STRMOM_DV}
      endToEndProt_TAR_STMOM_DV_ACT: end-to-end-profile={category=PROFILE_01, data-ids=179, data-id-mode=0, data-length=64, max-delta-counter-init=14, crc-offset=0, counter-offset=8}, end-to-end-protection-i-signal-i-pdu{data-offset=0, i-signal-group=sigGroup_TAR_STMOM_DV_ACT, i-signal-i-pdu=PDUs/TAR_STMOM_DV_ACT}
      endToEndProt_VYAW_VEH: end-to-end-profile={category=PROFILE_01, data-ids=14, data-id-mode=0, data-length=48, max-delta-counter-init=14, crc-offset=0, counter-offset=8}, end-to-end-protection-i-signal-i-pdu{data-offset=0, i-signal-group=sigGroup_VYAW_VEH, i-signal-i-pdu=PDUs/VYAW_VEH}
      endToEndProt_V_VEH: end-to-end-profile={category=PROFILE_01, data-ids=12, data-id-mode=0, data-length=40, max-delta-counter-init=14, crc-offset=0, counter-offset=8}, end-to-end-protection-i-signal-i-pdu{data-offset=0, i-signal-group=sigGroup_V_VEH, i-signal-i-pdu=PDUs/V_VEH}
package /Systems/ModeDeclarationGroups/BasePartialNetworks
  mode declaration group PWFVehicleState: initial-mode=PWFVehicleState/KEINE_KOMMUNIKATION
    mode KEINE_KOMMUNIKATION
    mode UNGUELTIG
  mode declaration group UNGUELTIG: initial-mode=UNGUELTIG/UNGUELTIG_OFF
    mode UNGUELTIG_OFF
    mode UNGUELTIG_ON
package /Systems/ModeDeclarationGroups/FunctionalPartialNetworks
  mode declaration group Ungueltig: initial-mode=Ungueltig/UNGUELTIG_OFF
    mode UNGUELTIG_OFF
    mode UNGUELTIG_ON
